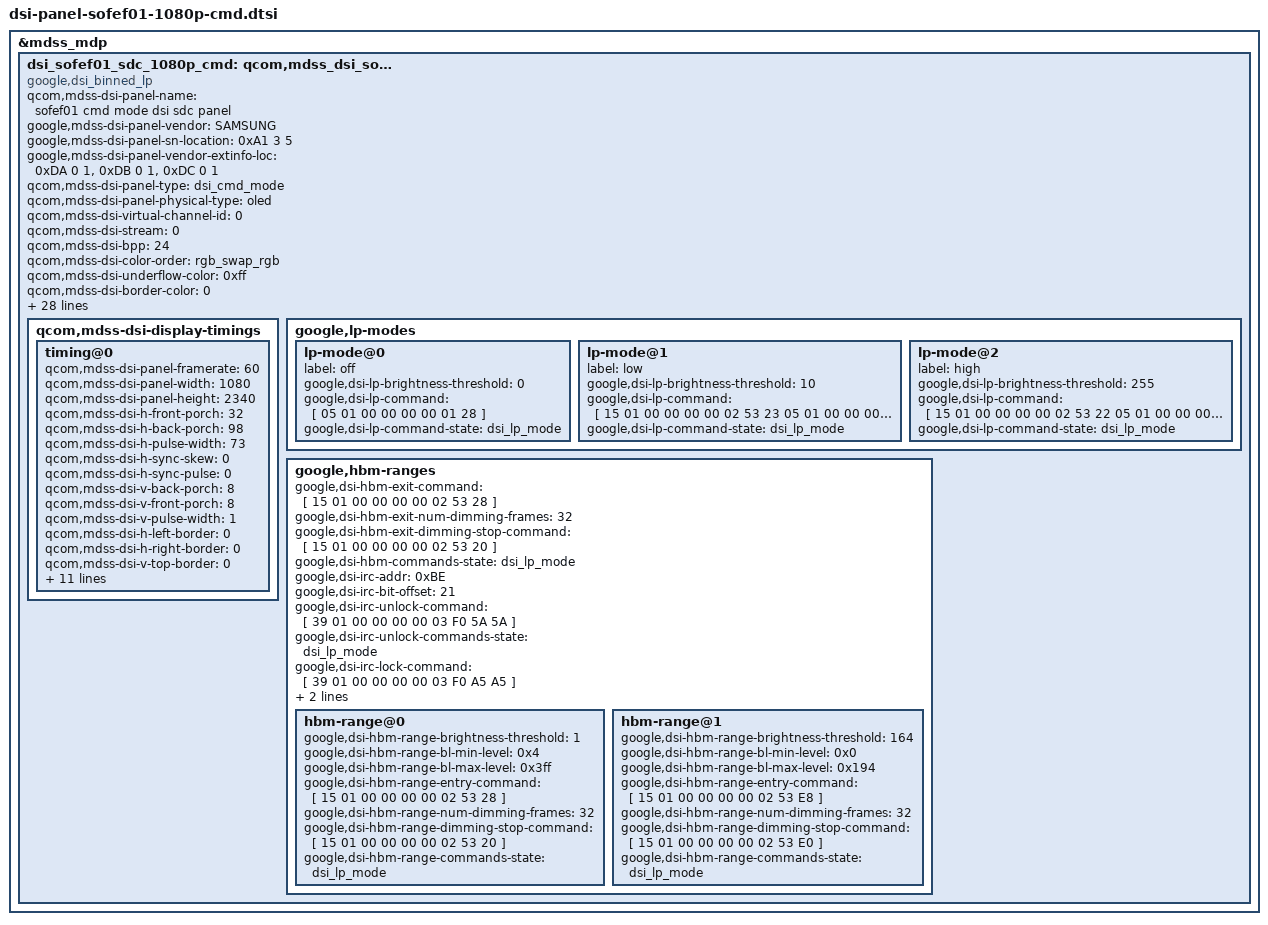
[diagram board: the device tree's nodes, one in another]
/* Copyright (c) 2019, The Linux Foundation. All rights reserved.
 *
 * This program is free software; you can redistribute it and/or modify
 * it under the terms of the GNU General Public License version 2 and
 * only version 2 as published by the Free Software Foundation.
 *
 * This program is distributed in the hope that it will be useful,
 * but WITHOUT ANY WARRANTY; without even the implied warranty of
 * MERCHANTABILITY or FITNESS FOR A PARTICULAR PURPOSE.  See the
 * GNU General Public License for more details.
 */

&mdss_mdp {
	dsi_sofef01_sdc_1080p_cmd: qcom,mdss_dsi_sofef01_sdc_1080p_cmd {
		compatible = "google,dsi_binned_lp";
		qcom,mdss-dsi-panel-name = "sofef01 cmd mode dsi sdc panel";
		google,mdss-dsi-panel-vendor = "SAMSUNG";
		google,mdss-dsi-panel-sn-location = <0xA1 3 5>;
		google,mdss-dsi-panel-vendor-extinfo-loc = <0xDA 0 1>,
							   <0xDB 0 1>,
							   <0xDC 0 1>;
		qcom,mdss-dsi-panel-type = "dsi_cmd_mode";
		qcom,mdss-dsi-panel-physical-type = "oled";
		qcom,mdss-dsi-virtual-channel-id = <0>;
		qcom,mdss-dsi-stream = <0>;
		qcom,mdss-dsi-bpp = <24>;
		qcom,mdss-dsi-color-order = "rgb_swap_rgb";
		qcom,mdss-dsi-underflow-color = <0xff>;
		qcom,mdss-dsi-border-color = <0>;
		qcom,mdss-dsi-traffic-mode = "burst_mode";
		qcom,mdss-dsi-lane-map = "lane_map_0123";
		qcom,mdss-dsi-bllp-eof-power-mode;
		qcom,mdss-dsi-bllp-power-mode;
		qcom,mdss-dsi-lane-0-state;
		qcom,mdss-dsi-lane-1-state;
		qcom,mdss-dsi-lane-2-state;
		qcom,mdss-dsi-lane-3-state;
		qcom,mdss-dsi-reset-sequence = <0 10>, <1 10>;
		qcom,mdss-dsi-dma-trigger = "trigger_sw";
		qcom,mdss-dsi-mdp-trigger = "none";
		qcom,mdss-dsi-te-pin-select = <1>;
		qcom,mdss-dsi-wr-mem-start = <0x2c>;
		qcom,mdss-dsi-wr-mem-continue = <0x3c>;
		qcom,mdss-dsi-te-dcs-command = <1>;
		qcom,mdss-dsi-te-check-enable;
		qcom,mdss-dsi-te-using-te-pin;
		qcom,mdss-dsi-lp11-init;
		qcom,mdss-dsi-tx-eot-append;

		qcom,mdss-pan-physical-width-dimension = <62>;
		qcom,mdss-pan-physical-height-dimension = <134>;
		qcom,mdss-dsi-bl-pmic-control-type = "bl_ctrl_dcs";
		qcom,mdss-dsi-bl-min-level = <4>;
		qcom,mdss-dsi-bl-max-level = <1023>; /* 10 bit */
		qcom,bl-update-flag = "delay_until_first_frame";

		qcom,mdss-dsi-bl-notifier-ranges = <30 50 70 200 255>;

		qcom,mdss-dsi-display-timings {
			timing@0 {
				qcom,mdss-dsi-panel-framerate = <60>;
				qcom,mdss-dsi-panel-width = <1080>;
				qcom,mdss-dsi-panel-height = <2340>;
				qcom,mdss-dsi-h-front-porch = <32>;
				qcom,mdss-dsi-h-back-porch = <98>;
				qcom,mdss-dsi-h-pulse-width = <73>;
				qcom,mdss-dsi-h-sync-skew = <0>;
				qcom,mdss-dsi-h-sync-pulse = <0>;
				qcom,mdss-dsi-v-back-porch = <8>;
				qcom,mdss-dsi-v-front-porch = <8>;
				qcom,mdss-dsi-v-pulse-width = <1>;
				qcom,mdss-dsi-h-left-border = <0>;
				qcom,mdss-dsi-h-right-border = <0>;
				qcom,mdss-dsi-v-top-border = <0>;
				qcom,mdss-dsi-v-bottom-border = <0>;
				qcom,mdss-dsi-on-command = [
					/* Sleep Out, Wait 10 ms */
					05 01 00 00 0A 00 01 11
					/* TE on */
					15 01 00 00 00 00 02 35 00
					/* MIC Setting */
					39 01 00 00 00 00 03 F0 5A 5A
					39 01 00 00 00 00 08 EB 17 41
						92 0E 10 82 5A
					39 01 00 00 00 00 03 F0 A5 A5
					/* CASET/PASET Setting */
					39 01 00 00 00 00 05 2A 00 00 04 37
					39 01 00 00 00 00 05 2B 00 00 09 23
					/* Brightness Setting */
					15 01 00 00 00 00 02 53 20
					/* H sync/V sync setting*/
					39 01 00 00 00 00 03 F0 5A 5A
					15 01 00 00 00 00 02 B0 09
					39 01 00 00 00 00 03 E8 11 30
					39 01 00 00 6E 00 03 F0 A5 A5
					/* Display On */
					05 01 00 00 00 00 01 29
				];
				qcom,mdss-dsi-off-command = [
					/* Display Off */
					05 01 00 00 14 00 01 28
					/* Sleep In */
					05 01 00 00 00 00 01 10
					/* VCI operating mode change */
					39 01 00 00 00 00 03 F0 5A 5A
					15 01 00 00 00 00 02 B0 05
					15 01 00 00 00 00 02 F4 01
					39 01 00 00 78 00 03 F0 A5 A5
				];
				qcom,mdss-dsi-lp1-command = [
					/* Display Off */
					05 01 00 00 00 00 01 28
					/* HLPM on: 50nit */
					15 01 00 00 11 00 02 53 22
				];
				qcom,mdss-dsi-nolp-command = [
					/* Display Off */
					05 01 00 00 00 00 01 28
					/* HLPM off */
					15 01 00 00 22 00 02 53 20
					/* Display On */
					05 01 00 00 00 00 01 29
				];
				qcom,mdss-dsi-on-command-state = "dsi_lp_mode";
				qcom,mdss-dsi-off-command-state = "dsi_lp_mode";
			};
		};

		google,lp-modes {
			lp-mode@0 {
				label = "off";
				google,dsi-lp-brightness-threshold = <0>;
				google,dsi-lp-command = [
					/* Display Off */
					05 01 00 00 00 00 01 28
				];
				google,dsi-lp-command-state = "dsi_lp_mode";
			};

			lp-mode@1 {
				label = "low";
				google,dsi-lp-brightness-threshold = <10>;
				google,dsi-lp-command = [
					/* HLPM on: 10nit */
					15 01 00 00 00 00 02 53 23
					/* Display On */
					05 01 00 00 00 00 01 29
				];
				google,dsi-lp-command-state = "dsi_lp_mode";
			};

			lp-mode@2 {
				label = "high";
				google,dsi-lp-brightness-threshold = <255>;
				google,dsi-lp-command = [
					/* HLPM on: 50nit */
					15 01 00 00 00 00 02 53 22
					/* Display On */
					05 01 00 00 00 00 01 29
				];
				google,dsi-lp-command-state = "dsi_lp_mode";
			};
		};

		google,hbm-ranges {
			google,dsi-hbm-exit-command = [
				/* Disable high brightness and enable
				 * brightness dimming
				 */
				15 01 00 00 00 00 02 53 28
			];
			google,dsi-hbm-exit-num-dimming-frames = <32>;
			google,dsi-hbm-exit-dimming-stop-command = [
				/* Disable high brightness and disable
				 * brightness dimming
				 */
				15 01 00 00 00 00 02 53 20
			];
			google,dsi-hbm-commands-state = "dsi_lp_mode";
			google,dsi-irc-addr = <0xBE>;
			google,dsi-irc-bit-offset = <21>;
			google,dsi-irc-unlock-command = [
				39 01 00 00 00 00 03 F0 5A 5A
			];
			google,dsi-irc-unlock-commands-state = "dsi_lp_mode";
			google,dsi-irc-lock-command = [
				39 01 00 00 00 00 03 F0 A5 A5
			];
			google,dsi-irc-lock-commands-state = "dsi_lp_mode";

			hbm-range@0 {
				google,dsi-hbm-range-brightness-threshold = <1>;

				google,dsi-hbm-range-bl-min-level = <0x4>;
				google,dsi-hbm-range-bl-max-level = <0x3ff>;
				google,dsi-hbm-range-entry-command = [
					/* Disable high brightness and enable
					 * brightness dimming
					 */
					15 01 00 00 00 00 02 53 28
				];
				google,dsi-hbm-range-num-dimming-frames = <32>;
				google,dsi-hbm-range-dimming-stop-command = [
					/* Disable high brightness and disable
					 * brightness dimming
					 */
					15 01 00 00 00 00 02 53 20
				];
				google,dsi-hbm-range-commands-state =
					"dsi_lp_mode";
			};

			hbm-range@1 {
				/* Normal brightness mode covers ~2 to 450
				 * nits, using panel brightness values up to
				 * 0x3ff. HBM extends the range to 700 nits,
				 * and remaps user brightness 1-255 to cover
				 * this extended range. In this extended range,
				 * 450 nits / 0x3ff corresponds to user
				 * brightness 164. Panel brightness is
				 * adjustable in the 470-700 nit segment.
				 */
				google,dsi-hbm-range-brightness-threshold =
					<164>;

				google,dsi-hbm-range-bl-min-level = <0x0>;
				google,dsi-hbm-range-bl-max-level = <0x194>;

				google,dsi-hbm-range-entry-command = [
					/* Enable high brightness and
					 * brightness dimming
					 */
					15 01 00 00 00 00 02 53 E8
				];
				google,dsi-hbm-range-num-dimming-frames = <32>;
				google,dsi-hbm-range-dimming-stop-command = [
					/* Enable high brightness and disable
					 * brightness dimming
					 */
					15 01 00 00 00 00 02 53 E0
				];
				google,dsi-hbm-range-commands-state =
					"dsi_lp_mode";
			};
		};
	};
};
